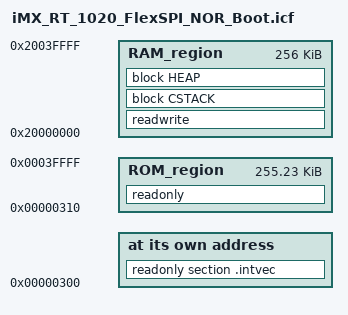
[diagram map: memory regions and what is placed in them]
/* iMX_RT_1020_FlexSPI_NOR.icf - for iMX RT 1020 running from SRAM */
/* 256k SRAM                                                       */
define symbol __ICFEDIT_intvec_start__ = 0x00000300;
/*-Memory Regions-*/
define symbol __ICFEDIT_region_ROM_start__  = 0x00000310; /* ITCM */
define symbol __ICFEDIT_region_ROM_end__    = 0x0003FFFF;
define symbol __ICFEDIT_region_RAM_start__  = 0x20000000; /* DTCM */
define symbol __ICFEDIT_region_RAM_end__    = 0x2003FFFF;
/*-Sizes-*/
define symbol __ICFEDIT_size_cstack__ = 0x0;
define symbol __ICFEDIT_size_heap__   = 0x0;
/**** End of ICF editor section. ###ICF###*/


define memory mem with size = 4G;
define region ROM_region   = mem:[from __ICFEDIT_region_ROM_start__ to __ICFEDIT_region_ROM_end__];
define region RAM_region   = mem:[from __ICFEDIT_region_RAM_start__ to __ICFEDIT_region_RAM_end__];

define block CSTACK    with alignment = 8, size = __ICFEDIT_size_cstack__   { };
define block HEAP      with alignment = 8, size = __ICFEDIT_size_heap__     { };

initialize by copy { readwrite };
do not initialize  { section .noinit };

place at address mem:__ICFEDIT_intvec_start__ { readonly section .intvec };

place in ROM_region   { readonly };
place in RAM_region   { readwrite, block CSTACK, block HEAP };
